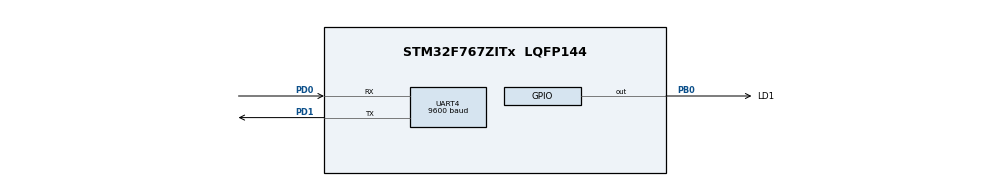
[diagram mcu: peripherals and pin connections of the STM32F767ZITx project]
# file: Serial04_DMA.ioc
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Dma.Request0=UART4_RX
Dma.UART4_RX.0.Direction=DMA_PERIPH_TO_MEMORY
Dma.UART4_RX.0.FIFOMode=DMA_FIFOMODE_DISABLE
Dma.UART4_RX.0.Instance=DMA1_Stream2
Dma.UART4_RX.0.MemDataAlignment=DMA_MDATAALIGN_BYTE
Dma.UART4_RX.0.MemInc=DMA_MINC_ENABLE
Dma.UART4_RX.0.Mode=DMA_CIRCULAR
Dma.UART4_RX.0.PeriphDataAlignment=DMA_PDATAALIGN_BYTE
Dma.UART4_RX.0.PeriphInc=DMA_PINC_DISABLE
Dma.UART4_RX.0.Priority=DMA_PRIORITY_LOW
Mcu.Family=STM32F7
Mcu.Name=STM32F767ZITx
Mcu.Package=LQFP144
NVIC.DMA1_Stream2_IRQn=true\:0\:0\:false\:false\:true\:false\:true\:true
NVIC.PriorityGroup=NVIC_PRIORITYGROUP_4
NVIC.UART4_IRQn=true\:0\:0\:false\:false\:true\:true\:true\:true
PB0.GPIO_Label=LD1
PB0.Signal=GPIO_Output
PD0.Mode=Asynchronous
PD0.Signal=UART4_RX
PD1.Mode=Asynchronous
PD1.Signal=UART4_TX
ProjectManager.HeapSize=0x200
ProjectManager.StackSize=0x400
ProjectManager.TargetToolchain=STM32CubeIDE
RCC.HSE_VALUE=25000000
RCC.HSI_VALUE=16000000
RCC.LSE_VALUE=32768
RCC.USBFreq_Value=96000000
RCC.VCOOutputFreq_Value=192000000
UART4.BaudRate=9600
board=custom

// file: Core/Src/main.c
/* USER CODE BEGIN Header */
/**
  ******************************************************************************
  * @file           : main.c
  * @brief          : Main program body
  ******************************************************************************
  * @attention
  *
  * Copyright (c) 2024 STMicroelectronics.
  * All rights reserved.
  *
  * This software is licensed under terms that can be found in the LICENSE file
  * in the root directory of this software component.
  * If no LICENSE file comes with this software, it is provided AS-IS.
  *
  ******************************************************************************
  */
/* USER CODE END Header */
#include "main.h"

/* USER CODE BEGIN Includes */
uint8_t brx[4],error_bff=0;
/* USER CODE END Includes */

UART_HandleTypeDef huart4;
DMA_HandleTypeDef hdma_uart4_rx;

/* USER CODE BEGIN PV */
HAL_UART_StateTypeDef uart_error;
HAL_UART_StateTypeDef uart_status;
/* USER CODE END PV */

void SystemClock_Config(void);
static void MX_GPIO_Init(void);
static void MX_DMA_Init(void);
static void MX_UART4_Init(void);

/* USER CODE BEGIN 0 */
void HAL_UART_RxCpltCallback(UART_HandleTypeDef *huart)
{
	if(brx[0] == 'c' && brx[1] == 'h' && brx[2] == 'n' && brx[3] == 'g')
	{
		HAL_GPIO_TogglePin(GPIOB, LD1_Pin);
	}

}
/* USER CODE END 0 */

int main(void)
{

  /* MCU Configuration--------------------------------------------------------*/

  /* Reset of all peripherals, Initializes the Flash interface and the Systick. */
  HAL_Init();

  /* Configure the system clock */
  SystemClock_Config();

  /* Initialize all configured peripherals */
  MX_GPIO_Init();
  MX_DMA_Init();
  MX_UART4_Init();
  /* USER CODE BEGIN 2 */
  HAL_UART_Receive_DMA(&huart4, brx, 4);
  /* USER CODE END 2 */

  /* Infinite loop */
  while (1)
  {

    /* USER CODE BEGIN 3 */
	  switch(uart_error){
	  case HAL_UART_ERROR_NONE:
		  error_bff = 1;
	  	  break;
	  case HAL_UART_ERROR_PE:
	  	  error_bff = 2;
	  	  break;
	  case HAL_UART_ERROR_NE:
	  	  error_bff = 3;
	  	  break;
	  case HAL_UART_ERROR_FE:
	  	  error_bff = 4;
	  	  break;
	  case HAL_UART_ERROR_ORE:
	  	  error_bff = 5;
	  	  break;
	  case HAL_UART_ERROR_DMA:
	  	  error_bff = 6;
	  	  break;
	  case HAL_UART_ERROR_RTO:
	  	  error_bff = 7;
	  	  break;
	  }
	  HAL_UART_Transmit(&huart4, "STM32Curso\r\n", 12, 100);
	  HAL_Delay(1000);
	  uart_error = HAL_UART_GetError(&huart4);
	  uart_status = HAL_UART_GetState(&huart4);

 // HAL_UART_ERROR_NONE             (0x00000000U)    /*!< No error                */
 // HAL_UART_ERROR_PE               (0x00000001U)    /*!< Parity error            */
 // HAL_UART_ERROR_NE               (0x00000002U)    /*!< Noise error             */
 // HAL_UART_ERROR_FE               (0x00000004U)    /*!< Frame error             */
 // HAL_UART_ERROR_ORE              (0x00000008U)    /*!< Overrun error           */
 // HAL_UART_ERROR_DMA              (0x00000010U)    /*!< DMA transfer error      */
 // HAL_UART_ERROR_RTO              (0x00000020U)    /*!< Receiver Timeout error  */

  }
  /* USER CODE END 3 */
}

void SystemClock_Config(void)
{
  RCC_OscInitTypeDef RCC_OscInitStruct = {0};
  RCC_ClkInitTypeDef RCC_ClkInitStruct = {0};

  /** Configure the main internal regulator output voltage
  */
  __HAL_RCC_PWR_CLK_ENABLE();
  __HAL_PWR_VOLTAGESCALING_CONFIG(PWR_REGULATOR_VOLTAGE_SCALE3);

  /** Initializes the RCC Oscillators according to the specified parameters
  * in the RCC_OscInitTypeDef structure.
  */
  RCC_OscInitStruct.OscillatorType = RCC_OSCILLATORTYPE_HSI;
  RCC_OscInitStruct.HSIState = RCC_HSI_ON;
  RCC_OscInitStruct.HSICalibrationValue = RCC_HSICALIBRATION_DEFAULT;
  RCC_OscInitStruct.PLL.PLLState = RCC_PLL_NONE;
  if (HAL_RCC_OscConfig(&RCC_OscInitStruct) != HAL_OK)
  {
    Error_Handler();
  }

  /** Initializes the CPU, AHB and APB buses clocks
  */
  RCC_ClkInitStruct.ClockType = RCC_CLOCKTYPE_HCLK|RCC_CLOCKTYPE_SYSCLK
                              |RCC_CLOCKTYPE_PCLK1|RCC_CLOCKTYPE_PCLK2;
  RCC_ClkInitStruct.SYSCLKSource = RCC_SYSCLKSOURCE_HSI;
  RCC_ClkInitStruct.AHBCLKDivider = RCC_SYSCLK_DIV1;
  RCC_ClkInitStruct.APB1CLKDivider = RCC_HCLK_DIV1;
  RCC_ClkInitStruct.APB2CLKDivider = RCC_HCLK_DIV1;

  if (HAL_RCC_ClockConfig(&RCC_ClkInitStruct, FLASH_LATENCY_0) != HAL_OK)
  {
    Error_Handler();
  }
}

static void MX_UART4_Init(void)
{

  huart4.Instance = UART4;
  huart4.Init.BaudRate = 9600;
  huart4.Init.WordLength = UART_WORDLENGTH_8B;
  huart4.Init.StopBits = UART_STOPBITS_1;
  huart4.Init.Parity = UART_PARITY_NONE;
  huart4.Init.Mode = UART_MODE_TX_RX;
  huart4.Init.HwFlowCtl = UART_HWCONTROL_NONE;
  huart4.Init.OverSampling = UART_OVERSAMPLING_16;
  huart4.Init.OneBitSampling = UART_ONE_BIT_SAMPLE_DISABLE;
  huart4.AdvancedInit.AdvFeatureInit = UART_ADVFEATURE_NO_INIT;
  if (HAL_UART_Init(&huart4) != HAL_OK)
  {
    Error_Handler();
  }

}

static void MX_DMA_Init(void)
{

  /* DMA controller clock enable */
  __HAL_RCC_DMA1_CLK_ENABLE();

  /* DMA interrupt init */
  /* DMA1_Stream2_IRQn interrupt configuration */
  HAL_NVIC_SetPriority(DMA1_Stream2_IRQn, 0, 0);
  HAL_NVIC_EnableIRQ(DMA1_Stream2_IRQn);

}

static void MX_GPIO_Init(void)
{
  GPIO_InitTypeDef GPIO_InitStruct = {0};

  /* GPIO Ports Clock Enable */
  __HAL_RCC_GPIOB_CLK_ENABLE();
  __HAL_RCC_GPIOD_CLK_ENABLE();

  /*Configure GPIO pin Output Level */
  HAL_GPIO_WritePin(LD1_GPIO_Port, LD1_Pin, GPIO_PIN_RESET);

  /*Configure GPIO pin : LD1_Pin */
  GPIO_InitStruct.Pin = LD1_Pin;
  GPIO_InitStruct.Mode = GPIO_MODE_OUTPUT_PP;
  GPIO_InitStruct.Pull = GPIO_NOPULL;
  GPIO_InitStruct.Speed = GPIO_SPEED_FREQ_LOW;
  HAL_GPIO_Init(LD1_GPIO_Port, &GPIO_InitStruct);

}

void Error_Handler(void)
{
  __disable_irq();
  while (1)
  {
  }
}
